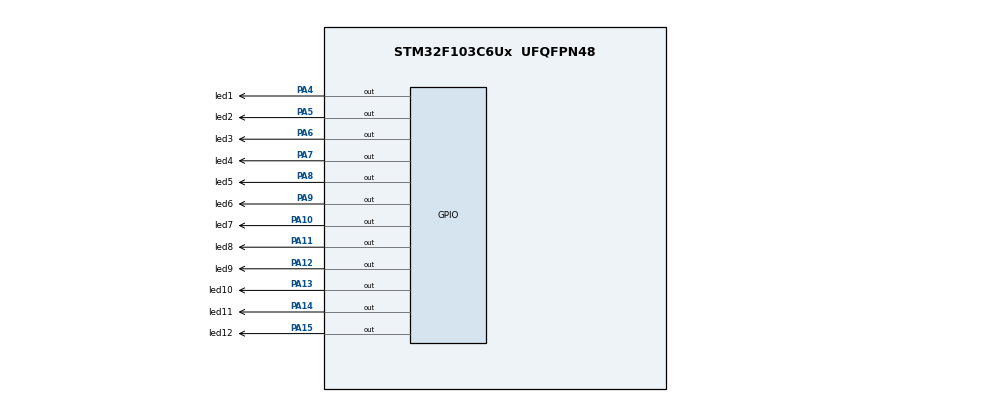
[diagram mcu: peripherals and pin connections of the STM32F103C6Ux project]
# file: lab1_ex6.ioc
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Mcu.Family=STM32F1
Mcu.Name=STM32F103C6Ux
Mcu.Package=UFQFPN48
NVIC.PriorityGroup=NVIC_PRIORITYGROUP_4
PA10.GPIO_Label=led7
PA10.Signal=GPIO_Output
PA11.GPIO_Label=led8
PA11.Signal=GPIO_Output
PA12.GPIO_Label=led9
PA12.Signal=GPIO_Output
PA13.GPIO_Label=led10
PA13.Signal=GPIO_Output
PA14.GPIO_Label=led11
PA14.Signal=GPIO_Output
PA15.GPIO_Label=led12
PA15.Signal=GPIO_Output
PA4.GPIO_Label=led1
PA4.Signal=GPIO_Output
PA5.GPIO_Label=led2
PA5.Signal=GPIO_Output
PA6.GPIO_Label=led3
PA6.Signal=GPIO_Output
PA7.GPIO_Label=led4
PA7.Signal=GPIO_Output
PA8.GPIO_Label=led5
PA8.Signal=GPIO_Output
PA9.GPIO_Label=led6
PA9.Signal=GPIO_Output
ProjectManager.HeapSize=0x200
ProjectManager.StackSize=0x400
ProjectManager.TargetToolchain=STM32CubeIDE
RCC.APB1Freq_Value=8000000
RCC.APB2Freq_Value=8000000
VP_SYS_VS_ND.Mode=No_Debug
board=custom

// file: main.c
/* USER CODE BEGIN Header */
/**
  ******************************************************************************
  * @file           : main.c
  * @brief          : Main program body
  ******************************************************************************
  * @attention
  *
  * <h2><center>&copy; Copyright (c) 2025 STMicroelectronics.
  * All rights reserved.</center></h2>
  *
  * This software component is licensed by ST under BSD 3-Clause license,
  * the "License"; You may not use this file except in compliance with the
  * License. You may obtain a copy of the License at:
  *                        opensource.org/licenses/BSD-3-Clause
  *
  ******************************************************************************
  */
/* USER CODE END Header */
#include "main.h"

void SystemClock_Config(void);
static void MX_GPIO_Init(void);

int main(void)
{

  /* MCU Configuration--------------------------------------------------------*/

  /* Reset of all peripherals, Initializes the Flash interface and the Systick. */
  HAL_Init();

  /* Configure the system clock */
  SystemClock_Config();

  /* Initialize all configured peripherals */
  MX_GPIO_Init();
void led12(int n) {
	switch (n) {
	case 1:
		HAL_GPIO_WritePin(led1_GPIO_Port, led1_Pin, SET);
		HAL_GPIO_WritePin(led2_GPIO_Port, led2_Pin, RESET);
		HAL_GPIO_WritePin(led3_GPIO_Port, led3_Pin, RESET);
		HAL_GPIO_WritePin(led4_GPIO_Port, led4_Pin, RESET);
		HAL_GPIO_WritePin(led5_GPIO_Port, led5_Pin, RESET);
		HAL_GPIO_WritePin(led6_GPIO_Port, led6_Pin, RESET);
		HAL_GPIO_WritePin(led7_GPIO_Port, led7_Pin, RESET);
		HAL_GPIO_WritePin(led8_GPIO_Port, led8_Pin, RESET);
		HAL_GPIO_WritePin(led9_GPIO_Port, led9_Pin, RESET);
		HAL_GPIO_WritePin(led10_GPIO_Port, led10_Pin, RESET);
		HAL_GPIO_WritePin(led11_GPIO_Port, led11_Pin, RESET);
		HAL_GPIO_WritePin(led12_GPIO_Port, led12_Pin, RESET);
		break;
	case 2:
		HAL_GPIO_WritePin(led1_GPIO_Port, led1_Pin, SET);
				HAL_GPIO_WritePin(led2_GPIO_Port, led2_Pin, SET);
				HAL_GPIO_WritePin(led3_GPIO_Port, led3_Pin, RESET);
				HAL_GPIO_WritePin(led4_GPIO_Port, led4_Pin, RESET);
				HAL_GPIO_WritePin(led5_GPIO_Port, led5_Pin, RESET);
				HAL_GPIO_WritePin(led6_GPIO_Port, led6_Pin, RESET);
				HAL_GPIO_WritePin(led7_GPIO_Port, led7_Pin, RESET);
				HAL_GPIO_WritePin(led8_GPIO_Port, led8_Pin, RESET);
				HAL_GPIO_WritePin(led9_GPIO_Port, led9_Pin, RESET);
				HAL_GPIO_WritePin(led10_GPIO_Port, led10_Pin, RESET);
				HAL_GPIO_WritePin(led11_GPIO_Port, led11_Pin, RESET);
				HAL_GPIO_WritePin(led12_GPIO_Port, led12_Pin, RESET);
				break;
	case 3:
		HAL_GPIO_WritePin(led1_GPIO_Port, led1_Pin, SET);
				HAL_GPIO_WritePin(led2_GPIO_Port, led2_Pin, SET);
				HAL_GPIO_WritePin(led3_GPIO_Port, led3_Pin, SET);
				HAL_GPIO_WritePin(led4_GPIO_Port, led4_Pin, RESET);
				HAL_GPIO_WritePin(led5_GPIO_Port, led5_Pin, RESET);
				HAL_GPIO_WritePin(led6_GPIO_Port, led6_Pin, RESET);
				HAL_GPIO_WritePin(led7_GPIO_Port, led7_Pin, RESET);
				HAL_GPIO_WritePin(led8_GPIO_Port, led8_Pin, RESET);
				HAL_GPIO_WritePin(led9_GPIO_Port, led9_Pin, RESET);
				HAL_GPIO_WritePin(led10_GPIO_Port, led10_Pin, RESET);
				HAL_GPIO_WritePin(led11_GPIO_Port, led11_Pin, RESET);
				HAL_GPIO_WritePin(led12_GPIO_Port, led12_Pin, RESET);
				break;
	case 4:
		HAL_GPIO_WritePin(led1_GPIO_Port, led1_Pin, SET);
				HAL_GPIO_WritePin(led2_GPIO_Port, led2_Pin, SET);
				HAL_GPIO_WritePin(led3_GPIO_Port, led3_Pin, SET);
				HAL_GPIO_WritePin(led4_GPIO_Port, led4_Pin, SET);
				HAL_GPIO_WritePin(led5_GPIO_Port, led5_Pin, RESET);
				HAL_GPIO_WritePin(led6_GPIO_Port, led6_Pin, RESET);
				HAL_GPIO_WritePin(led7_GPIO_Port, led7_Pin, RESET);
				HAL_GPIO_WritePin(led8_GPIO_Port, led8_Pin, RESET);
				HAL_GPIO_WritePin(led9_GPIO_Port, led9_Pin, RESET);
				HAL_GPIO_WritePin(led10_GPIO_Port, led10_Pin, RESET);
				HAL_GPIO_WritePin(led11_GPIO_Port, led11_Pin, RESET);
				HAL_GPIO_WritePin(led12_GPIO_Port, led12_Pin, RESET);
				break;
	case 5:
		HAL_GPIO_WritePin(led1_GPIO_Port, led1_Pin, SET);
				HAL_GPIO_WritePin(led2_GPIO_Port, led2_Pin, SET);
				HAL_GPIO_WritePin(led3_GPIO_Port, led3_Pin, SET);
				HAL_GPIO_WritePin(led4_GPIO_Port, led4_Pin, SET);
				HAL_GPIO_WritePin(led5_GPIO_Port, led5_Pin, SET);
				HAL_GPIO_WritePin(led6_GPIO_Port, led6_Pin, RESET);
				HAL_GPIO_WritePin(led7_GPIO_Port, led7_Pin, RESET);
				HAL_GPIO_WritePin(led8_GPIO_Port, led8_Pin, RESET);
				HAL_GPIO_WritePin(led9_GPIO_Port, led9_Pin, RESET);
				HAL_GPIO_WritePin(led10_GPIO_Port, led10_Pin, RESET);
				HAL_GPIO_WritePin(led11_GPIO_Port, led11_Pin, RESET);
				HAL_GPIO_WritePin(led12_GPIO_Port, led12_Pin, RESET);
				break;
	case 6:
		HAL_GPIO_WritePin(led1_GPIO_Port, led1_Pin, SET);
				HAL_GPIO_WritePin(led2_GPIO_Port, led2_Pin, SET);
				HAL_GPIO_WritePin(led3_GPIO_Port, led3_Pin, SET);
				HAL_GPIO_WritePin(led4_GPIO_Port, led4_Pin, SET);
				HAL_GPIO_WritePin(led5_GPIO_Port, led5_Pin, SET);
				HAL_GPIO_WritePin(led6_GPIO_Port, led6_Pin, SET);
				HAL_GPIO_WritePin(led7_GPIO_Port, led7_Pin, RESET);
				HAL_GPIO_WritePin(led8_GPIO_Port, led8_Pin, RESET);
				HAL_GPIO_WritePin(led9_GPIO_Port, led9_Pin, RESET);
				HAL_GPIO_WritePin(led10_GPIO_Port, led10_Pin, RESET);
				HAL_GPIO_WritePin(led11_GPIO_Port, led11_Pin, RESET);
				HAL_GPIO_WritePin(led12_GPIO_Port, led12_Pin, RESET);
				break;
	case 7:
		HAL_GPIO_WritePin(led1_GPIO_Port, led1_Pin, SET);
				HAL_GPIO_WritePin(led2_GPIO_Port, led2_Pin, SET);
				HAL_GPIO_WritePin(led3_GPIO_Port, led3_Pin, SET);
				HAL_GPIO_WritePin(led4_GPIO_Port, led4_Pin, SET);
				HAL_GPIO_WritePin(led5_GPIO_Port, led5_Pin, SET);
				HAL_GPIO_WritePin(led6_GPIO_Port, led6_Pin, SET);
				HAL_GPIO_WritePin(led7_GPIO_Port, led7_Pin, SET);
				HAL_GPIO_WritePin(led8_GPIO_Port, led8_Pin, RESET);
				HAL_GPIO_WritePin(led9_GPIO_Port, led9_Pin, RESET);
				HAL_GPIO_WritePin(led10_GPIO_Port, led10_Pin, RESET);
				HAL_GPIO_WritePin(led11_GPIO_Port, led11_Pin, RESET);
				HAL_GPIO_WritePin(led12_GPIO_Port, led12_Pin, RESET);
				break;
	case 8:
		HAL_GPIO_WritePin(led1_GPIO_Port, led1_Pin, SET);
				HAL_GPIO_WritePin(led2_GPIO_Port, led2_Pin, SET);
				HAL_GPIO_WritePin(led3_GPIO_Port, led3_Pin, SET);
				HAL_GPIO_WritePin(led4_GPIO_Port, led4_Pin, SET);
				HAL_GPIO_WritePin(led5_GPIO_Port, led5_Pin, SET);
				HAL_GPIO_WritePin(led6_GPIO_Port, led6_Pin, SET);
				HAL_GPIO_WritePin(led7_GPIO_Port, led7_Pin, SET);
				HAL_GPIO_WritePin(led8_GPIO_Port, led8_Pin, SET);
				HAL_GPIO_WritePin(led9_GPIO_Port, led9_Pin, RESET);
				HAL_GPIO_WritePin(led10_GPIO_Port, led10_Pin, RESET);
				HAL_GPIO_WritePin(led11_GPIO_Port, led11_Pin, RESET);
				HAL_GPIO_WritePin(led12_GPIO_Port, led12_Pin, RESET);
				break;
	case 9:
		HAL_GPIO_WritePin(led1_GPIO_Port, led1_Pin, SET);
				HAL_GPIO_WritePin(led2_GPIO_Port, led2_Pin, SET);
				HAL_GPIO_WritePin(led3_GPIO_Port, led3_Pin, SET);
				HAL_GPIO_WritePin(led4_GPIO_Port, led4_Pin, SET);
				HAL_GPIO_WritePin(led5_GPIO_Port, led5_Pin, SET);
				HAL_GPIO_WritePin(led6_GPIO_Port, led6_Pin, SET);
				HAL_GPIO_WritePin(led7_GPIO_Port, led7_Pin, SET);
				HAL_GPIO_WritePin(led8_GPIO_Port, led8_Pin, SET);
				HAL_GPIO_WritePin(led9_GPIO_Port, led9_Pin, SET);
				HAL_GPIO_WritePin(led10_GPIO_Port, led10_Pin, RESET);
				HAL_GPIO_WritePin(led11_GPIO_Port, led11_Pin, RESET);
				HAL_GPIO_WritePin(led12_GPIO_Port, led12_Pin, RESET);
				break;
	case 10:
		HAL_GPIO_WritePin(led1_GPIO_Port, led1_Pin, SET);
				HAL_GPIO_WritePin(led2_GPIO_Port, led2_Pin, SET);
				HAL_GPIO_WritePin(led3_GPIO_Port, led3_Pin, SET);
				HAL_GPIO_WritePin(led4_GPIO_Port, led4_Pin, SET);
				HAL_GPIO_WritePin(led5_GPIO_Port, led5_Pin, SET);
				HAL_GPIO_WritePin(led6_GPIO_Port, led6_Pin, SET);
				HAL_GPIO_WritePin(led7_GPIO_Port, led7_Pin, SET);
				HAL_GPIO_WritePin(led8_GPIO_Port, led8_Pin, SET);
				HAL_GPIO_WritePin(led9_GPIO_Port, led9_Pin, SET);
				HAL_GPIO_WritePin(led10_GPIO_Port, led10_Pin, SET);
				HAL_GPIO_WritePin(led11_GPIO_Port, led11_Pin, RESET);
				HAL_GPIO_WritePin(led12_GPIO_Port, led12_Pin, RESET);
				break;
	case 11:
		HAL_GPIO_WritePin(led1_GPIO_Port, led1_Pin, SET);
				HAL_GPIO_WritePin(led2_GPIO_Port, led2_Pin, SET);
				HAL_GPIO_WritePin(led3_GPIO_Port, led3_Pin, SET);
				HAL_GPIO_WritePin(led4_GPIO_Port, led4_Pin, SET);
				HAL_GPIO_WritePin(led5_GPIO_Port, led5_Pin, SET);
				HAL_GPIO_WritePin(led6_GPIO_Port, led6_Pin, SET);
				HAL_GPIO_WritePin(led7_GPIO_Port, led7_Pin, SET);
				HAL_GPIO_WritePin(led8_GPIO_Port, led8_Pin, SET);
				HAL_GPIO_WritePin(led9_GPIO_Port, led9_Pin, SET);
				HAL_GPIO_WritePin(led10_GPIO_Port, led10_Pin, SET);
				HAL_GPIO_WritePin(led11_GPIO_Port, led11_Pin, SET);
				HAL_GPIO_WritePin(led12_GPIO_Port, led12_Pin, RESET);
				break;
	case 12:
		HAL_GPIO_WritePin(led1_GPIO_Port, led1_Pin, SET);
				HAL_GPIO_WritePin(led2_GPIO_Port, led2_Pin, SET);
				HAL_GPIO_WritePin(led3_GPIO_Port, led3_Pin, SET);
				HAL_GPIO_WritePin(led4_GPIO_Port, led4_Pin, SET);
				HAL_GPIO_WritePin(led5_GPIO_Port, led5_Pin, SET);
				HAL_GPIO_WritePin(led6_GPIO_Port, led6_Pin, SET);
				HAL_GPIO_WritePin(led7_GPIO_Port, led7_Pin, SET);
				HAL_GPIO_WritePin(led8_GPIO_Port, led8_Pin, SET);
				HAL_GPIO_WritePin(led9_GPIO_Port, led9_Pin, SET);
				HAL_GPIO_WritePin(led10_GPIO_Port, led10_Pin, SET);
				HAL_GPIO_WritePin(led11_GPIO_Port, led11_Pin, SET);
				HAL_GPIO_WritePin(led12_GPIO_Port, led12_Pin, SET);
				break;
	default:
		HAL_GPIO_WritePin(led1_GPIO_Port, led1_Pin, RESET);
						HAL_GPIO_WritePin(led2_GPIO_Port, led2_Pin, RESET);
						HAL_GPIO_WritePin(led3_GPIO_Port, led3_Pin, RESET);
						HAL_GPIO_WritePin(led4_GPIO_Port, led4_Pin, RESET);
						HAL_GPIO_WritePin(led5_GPIO_Port, led5_Pin, RESET);
						HAL_GPIO_WritePin(led6_GPIO_Port, led6_Pin, RESET);
						HAL_GPIO_WritePin(led7_GPIO_Port, led7_Pin, RESET);
						HAL_GPIO_WritePin(led8_GPIO_Port, led8_Pin, RESET);
						HAL_GPIO_WritePin(led9_GPIO_Port, led9_Pin, RESET);
						HAL_GPIO_WritePin(led10_GPIO_Port, led10_Pin, RESET);
						HAL_GPIO_WritePin(led11_GPIO_Port, led11_Pin, RESET);
						HAL_GPIO_WritePin(led12_GPIO_Port, led12_Pin, RESET);
						break;

	}
}
  /* Infinite loop */
  /* USER CODE BEGIN WHILE */
 int count = 0;
  while (1)
  {
    /* USER CODE END WHILE */
	  if (count > 12 ) count = 1;
	  led12(count++);
	  HAL_Delay(1000);

  }
}

void SystemClock_Config(void)
{
  RCC_OscInitTypeDef RCC_OscInitStruct = {0};
  RCC_ClkInitTypeDef RCC_ClkInitStruct = {0};

  /** Initializes the RCC Oscillators according to the specified parameters
  * in the RCC_OscInitTypeDef structure.
  */
  RCC_OscInitStruct.OscillatorType = RCC_OSCILLATORTYPE_HSI;
  RCC_OscInitStruct.HSIState = RCC_HSI_ON;
  RCC_OscInitStruct.HSICalibrationValue = RCC_HSICALIBRATION_DEFAULT;
  RCC_OscInitStruct.PLL.PLLState = RCC_PLL_NONE;
  if (HAL_RCC_OscConfig(&RCC_OscInitStruct) != HAL_OK)
  {
    Error_Handler();
  }
  /** Initializes the CPU, AHB and APB buses clocks
  */
  RCC_ClkInitStruct.ClockType = RCC_CLOCKTYPE_HCLK|RCC_CLOCKTYPE_SYSCLK
                              |RCC_CLOCKTYPE_PCLK1|RCC_CLOCKTYPE_PCLK2;
  RCC_ClkInitStruct.SYSCLKSource = RCC_SYSCLKSOURCE_HSI;
  RCC_ClkInitStruct.AHBCLKDivider = RCC_SYSCLK_DIV1;
  RCC_ClkInitStruct.APB1CLKDivider = RCC_HCLK_DIV1;
  RCC_ClkInitStruct.APB2CLKDivider = RCC_HCLK_DIV1;

  if (HAL_RCC_ClockConfig(&RCC_ClkInitStruct, FLASH_LATENCY_0) != HAL_OK)
  {
    Error_Handler();
  }
}

static void MX_GPIO_Init(void)
{
  GPIO_InitTypeDef GPIO_InitStruct = {0};

  /* GPIO Ports Clock Enable */
  __HAL_RCC_GPIOA_CLK_ENABLE();

  /*Configure GPIO pin Output Level */
  HAL_GPIO_WritePin(GPIOA, led1_Pin|led2_Pin|led3_Pin|led4_Pin
                          |led5_Pin|led6_Pin|led7_Pin|led8_Pin
                          |led9_Pin|led10_Pin|led11_Pin|led12_Pin, GPIO_PIN_RESET);

  /*Configure GPIO pins : led1_Pin led2_Pin led3_Pin led4_Pin
                           led5_Pin led6_Pin led7_Pin led8_Pin
                           led9_Pin led10_Pin led11_Pin led12_Pin */
  GPIO_InitStruct.Pin = led1_Pin|led2_Pin|led3_Pin|led4_Pin
                          |led5_Pin|led6_Pin|led7_Pin|led8_Pin
                          |led9_Pin|led10_Pin|led11_Pin|led12_Pin;
  GPIO_InitStruct.Mode = GPIO_MODE_OUTPUT_PP;
  GPIO_InitStruct.Pull = GPIO_NOPULL;
  GPIO_InitStruct.Speed = GPIO_SPEED_FREQ_LOW;
  HAL_GPIO_Init(GPIOA, &GPIO_InitStruct);

}

void Error_Handler(void)
{
  __disable_irq();
  while (1)
  {
  }
}

/************************ (C) COPYRIGHT STMicroelectronics *****END OF FILE****/
